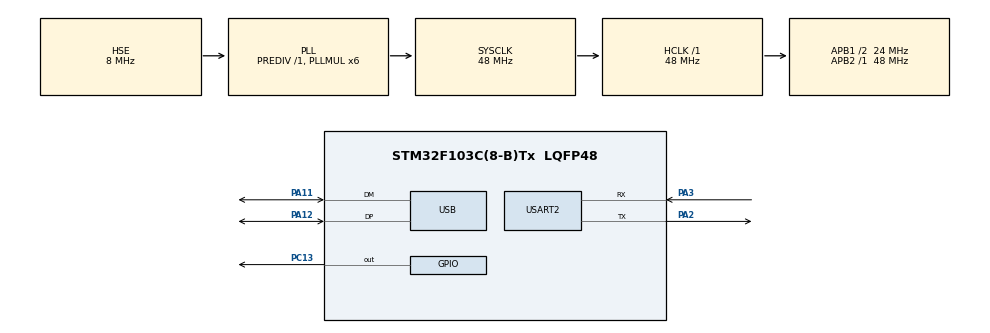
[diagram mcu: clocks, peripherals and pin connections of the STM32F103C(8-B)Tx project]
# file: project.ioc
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Dma.Request0=USART2_RX
Dma.Request1=USART2_TX
Dma.USART2_RX.0.Direction=DMA_PERIPH_TO_MEMORY
Dma.USART2_RX.0.Instance=DMA1_Channel6
Dma.USART2_RX.0.MemDataAlignment=DMA_MDATAALIGN_BYTE
Dma.USART2_RX.0.MemInc=DMA_MINC_ENABLE
Dma.USART2_RX.0.Mode=DMA_CIRCULAR
Dma.USART2_RX.0.PeriphDataAlignment=DMA_PDATAALIGN_BYTE
Dma.USART2_RX.0.PeriphInc=DMA_PINC_DISABLE
Dma.USART2_RX.0.Priority=DMA_PRIORITY_LOW
Dma.USART2_TX.1.Direction=DMA_MEMORY_TO_PERIPH
Dma.USART2_TX.1.Instance=DMA1_Channel7
Dma.USART2_TX.1.MemDataAlignment=DMA_MDATAALIGN_BYTE
Dma.USART2_TX.1.MemInc=DMA_MINC_ENABLE
Dma.USART2_TX.1.Mode=DMA_NORMAL
Dma.USART2_TX.1.PeriphDataAlignment=DMA_PDATAALIGN_BYTE
Dma.USART2_TX.1.PeriphInc=DMA_PINC_DISABLE
Dma.USART2_TX.1.Priority=DMA_PRIORITY_LOW
FREERTOS.Tasks01=defaultTask,24,128,StartDefaultTask,Default,NULL,Dynamic,NULL,NULL
Mcu.Family=STM32F1
Mcu.Name=STM32F103C(8-B)Tx
Mcu.Package=LQFP48
NVIC.DMA1_Channel6_IRQn=true\:5\:0\:false\:false\:true\:true\:false\:true\:true
NVIC.DMA1_Channel7_IRQn=true\:5\:0\:false\:false\:true\:true\:false\:true\:true
NVIC.PriorityGroup=NVIC_PRIORITYGROUP_4
NVIC.TIM2_IRQn=true\:15\:0\:false\:false\:true\:false\:false\:true\:true
NVIC.TimeBase=TIM2_IRQn
NVIC.TimeBaseIP=TIM2
NVIC.USART2_IRQn=true\:5\:0\:false\:false\:true\:true\:true\:true\:true
NVIC.USB_LP_CAN1_RX0_IRQn=true\:5\:0\:false\:false\:true\:true\:false\:true\:true
PA11.Mode=Device
PA11.Signal=USB_DM
PA12.Mode=Device
PA12.Signal=USB_DP
PA13.Mode=Serial_Wire
PA13.Signal=SYS_JTMS-SWDIO
PA14.Mode=Serial_Wire
PA14.Signal=SYS_JTCK-SWCLK
PA2.Mode=Asynchronous
PA2.Signal=USART2_TX
PA3.Mode=Asynchronous
PA3.Signal=USART2_RX
PC13-TAMPER-RTC.Signal=GPIO_Output
PC14-OSC32_IN.Mode=LSE-External-Oscillator
PC14-OSC32_IN.Signal=RCC_OSC32_IN
PC15-OSC32_OUT.Mode=LSE-External-Oscillator
PC15-OSC32_OUT.Signal=RCC_OSC32_OUT
PD0-OSC_IN.Mode=HSE-External-Oscillator
PD0-OSC_IN.Signal=RCC_OSC_IN
PD1-OSC_OUT.Mode=HSE-External-Oscillator
PD1-OSC_OUT.Signal=RCC_OSC_OUT
ProjectManager.HeapSize=0x200
ProjectManager.StackSize=0x400
ProjectManager.TargetToolchain=CMake
RCC.AHBFreq_Value=48000000
RCC.APB1CLKDivider=RCC_HCLK_DIV2
RCC.APB1Freq_Value=24000000
RCC.APB1TimFreq_Value=48000000
RCC.APB2Freq_Value=48000000
RCC.APB2TimFreq_Value=48000000
RCC.HCLKFreq_Value=48000000
RCC.PLLMUL=RCC_PLL_MUL6
RCC.PLLSourceVirtual=RCC_PLLSOURCE_HSE
RCC.SYSCLKFreq_VALUE=48000000
RCC.SYSCLKSource=RCC_SYSCLKSOURCE_PLLCLK
RCC.USBFreq_Value=48000000
USART2.VirtualMode=VM_ASYNC
USB_DEVICE.CLASS_NAME_FS=CDC
USB_DEVICE.VirtualMode=Cdc
USB_DEVICE.VirtualModeFS=Cdc_FS
VP_FREERTOS_VS_CMSIS_V2.Mode=CMSIS_V2
VP_SYS_VS_tim2.Mode=TIM2
VP_USB_DEVICE_VS_USB_DEVICE_CDC_FS.Mode=CDC_FS
board=custom

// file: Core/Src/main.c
/* USER CODE BEGIN Header */
/**
  ******************************************************************************
  * @file           : main.c
  * @brief          : Main program body
  ******************************************************************************
  * @attention
  *
  * Copyright (c) 2025 STMicroelectronics.
  * All rights reserved.
  *
  * This software is licensed under terms that can be found in the LICENSE file
  * in the root directory of this software component.
  * If no LICENSE file comes with this software, it is provided AS-IS.
  *
  ******************************************************************************
  */
/* USER CODE END Header */
#include "main.h"
#include "cmsis_os.h"
#include "dma.h"
#include "usart.h"
#include "usb_device.h"
#include "gpio.h"

void SystemClock_Config(void);
void MX_FREERTOS_Init(void);

int main(void)
{

  /* MCU Configuration--------------------------------------------------------*/

  /* Reset of all peripherals, Initializes the Flash interface and the Systick. */
  HAL_Init();

  /* USER CODE BEGIN Init */
  extern void USB_CDC_Hack_Reset(void);
  USB_CDC_Hack_Reset();
  /* USER CODE END Init */

  /* Configure the system clock */
  SystemClock_Config();

  /* Initialize all configured peripherals */
  MX_GPIO_Init();
  MX_DMA_Init();
  MX_USART2_UART_Init();
  /* USER CODE BEGIN 2 */
  // extern void user_main(void);
  // user_main();
  /* USER CODE END 2 */

  /* Init scheduler */
  osKernelInitialize();  /* Call init function for freertos objects (in cmsis_os2.c) */
  MX_FREERTOS_Init();

  /* Start scheduler */
  osKernelStart();

  /* We should never get here as control is now taken by the scheduler */

  /* Infinite loop */
  while (1)
  {

  }
}

void SystemClock_Config(void)
{
  RCC_OscInitTypeDef RCC_OscInitStruct = {0};
  RCC_ClkInitTypeDef RCC_ClkInitStruct = {0};
  RCC_PeriphCLKInitTypeDef PeriphClkInit = {0};

  /** Initializes the RCC Oscillators according to the specified parameters
  * in the RCC_OscInitTypeDef structure.
  */
  RCC_OscInitStruct.OscillatorType = RCC_OSCILLATORTYPE_HSE;
  RCC_OscInitStruct.HSEState = RCC_HSE_ON;
  RCC_OscInitStruct.HSEPredivValue = RCC_HSE_PREDIV_DIV1;
  RCC_OscInitStruct.HSIState = RCC_HSI_ON;
  RCC_OscInitStruct.PLL.PLLState = RCC_PLL_ON;
  RCC_OscInitStruct.PLL.PLLSource = RCC_PLLSOURCE_HSE;
  RCC_OscInitStruct.PLL.PLLMUL = RCC_PLL_MUL6;
  if (HAL_RCC_OscConfig(&RCC_OscInitStruct) != HAL_OK)
  {
    Error_Handler();
  }

  /** Initializes the CPU, AHB and APB buses clocks
  */
  RCC_ClkInitStruct.ClockType = RCC_CLOCKTYPE_HCLK|RCC_CLOCKTYPE_SYSCLK
                              |RCC_CLOCKTYPE_PCLK1|RCC_CLOCKTYPE_PCLK2;
  RCC_ClkInitStruct.SYSCLKSource = RCC_SYSCLKSOURCE_PLLCLK;
  RCC_ClkInitStruct.AHBCLKDivider = RCC_SYSCLK_DIV1;
  RCC_ClkInitStruct.APB1CLKDivider = RCC_HCLK_DIV2;
  RCC_ClkInitStruct.APB2CLKDivider = RCC_HCLK_DIV1;

  if (HAL_RCC_ClockConfig(&RCC_ClkInitStruct, FLASH_LATENCY_1) != HAL_OK)
  {
    Error_Handler();
  }
  PeriphClkInit.PeriphClockSelection = RCC_PERIPHCLK_USB;
  PeriphClkInit.UsbClockSelection = RCC_USBCLKSOURCE_PLL;
  if (HAL_RCCEx_PeriphCLKConfig(&PeriphClkInit) != HAL_OK)
  {
    Error_Handler();
  }
}

void HAL_TIM_PeriodElapsedCallback(TIM_HandleTypeDef *htim)
{
  if (htim->Instance == TIM2)
  {
    HAL_IncTick();
  }
}

void Error_Handler(void)
{
  __disable_irq();
  while (1)
  {
  }
}

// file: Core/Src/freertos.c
/* USER CODE BEGIN Header */
/**
  ******************************************************************************
  * File Name          : freertos.c
  * Description        : Code for freertos applications
  ******************************************************************************
  * @attention
  *
  * Copyright (c) 2025 STMicroelectronics.
  * All rights reserved.
  *
  * This software is licensed under terms that can be found in the LICENSE file
  * in the root directory of this software component.
  * If no LICENSE file comes with this software, it is provided AS-IS.
  *
  ******************************************************************************
  */
/* USER CODE END Header */

#include "FreeRTOS.h"
#include "task.h"
#include "main.h"
#include "cmsis_os.h"

/* Definitions for defaultTask */
osThreadId_t defaultTaskHandle;
const osThreadAttr_t defaultTask_attributes = {
  .name = "defaultTask",
  .stack_size = 128 * 4,
  .priority = (osPriority_t) osPriorityNormal,
};

void StartDefaultTask(void *argument);

extern void MX_USB_DEVICE_Init(void);
void MX_FREERTOS_Init(void); /* (MISRA C 2004 rule 8.1) */

void MX_FREERTOS_Init(void) {

  /* Create the thread(s) */
  /* creation of defaultTask */
  defaultTaskHandle = osThreadNew(StartDefaultTask, NULL, &defaultTask_attributes);

}

void StartDefaultTask(void *argument)
{
  /* init code for USB_DEVICE */
  MX_USB_DEVICE_Init();
  /* USER CODE BEGIN StartDefaultTask */
  extern void app_main(void);
  app_main();
  vTaskDelete(NULL);
  /* Infinite loop */
  for(;;)
  {
    osDelay(1);
  }
  /* USER CODE END StartDefaultTask */
}
